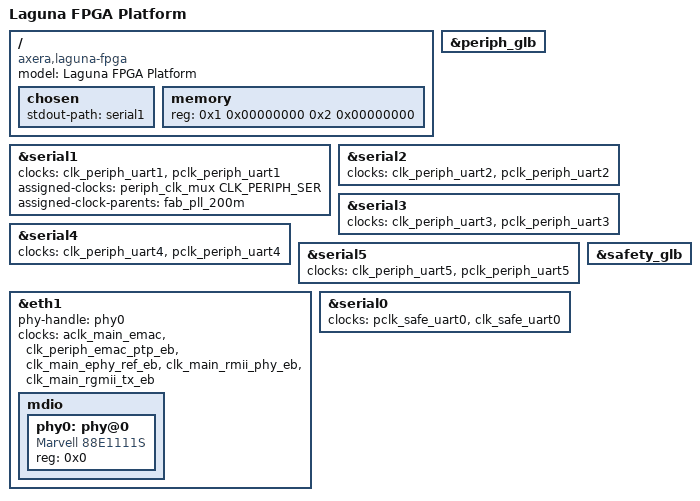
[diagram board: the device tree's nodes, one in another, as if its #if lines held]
/* SPDX-License-Identifier: GPL-2.0+
 *
 * Laguna FPGA Platform device tree
 *
 * Copyright (C) 2024 Charleye <wangkart@aliyun.com>
 */

/dts-v1/;
#include <dt-bindings/interrupt-controller/arm-gic.h>
#include <dt-bindings/mfd/laguna-syscon.h>
#include <dt-bindings/mfd/laguna-cru.h>
#include <dt-bindings/reset/laguna-reset.h>
#include <dt-bindings/clock/laguna-clock.h>

#include "laguna-global-ctrl.dtsi"
#include "laguna-clocks-fpga.dtsi"
#if defined(CONFIG_CLK_AXERA_V2)
#include "laguna-cru-v2.dtsi"
#elif defined(CONFIG_CLK_AXERA_V1)
#include "laguna-cru.dtsi"
#endif
#include "laguna.dtsi"

#if defined(CONFIG_LUA_SAFETY_INIT)
#include "laguna-safety-clocks-fpga.dtsi"
#if defined(CONFIG_CLK_AXERA_V2)
#include "laguna-safety-cru-v2.dtsi"
#elif defined(CONFIG_CLK_AXERA_V1)
#include "laguna-safety-cru.dtsi"
#endif
#include "laguna-safety.dtsi"
#endif

/ {
	model = "Laguna FPGA Platform";
	compatible = "axera,laguna-fpga";

	chosen {
		stdout-path = "serial1";
	};

	memory {
		reg = <0x1 0x00000000 0x2 0x00000000>;
		device_type = "memory";
	};
};

&periph_glb {
	status = "okay";
};

&serial1 {
#if defined(CONFIG_CLK_AXERA_V1)
	clocks = <&clk_periph_uart1>, <&pclk_periph_uart1>;
#elif defined(CONFIG_CLK_AXERA_V2)
	clocks = <&periph_clk_gate_0 PCLK_PERIPH_UART1>,
	         <&periph_clk_gate_0 CLK_PERIPH_UART1>;
#endif
	clock-names = "apb_pclk", "baudclk";
	status = "okay";
	assigned-clocks = <&periph_clk_mux CLK_PERIPH_SER>;
	assigned-clock-parents = <&fab_pll_200m>;
};

&serial2 {
#if defined(CONFIG_CLK_AXERA_V1)
	clocks = <&clk_periph_uart2>, <&pclk_periph_uart2>;
#elif defined(CONFIG_CLK_AXERA_V2)
	clocks = <&periph_clk_gate_0 PCLK_PERIPH_UART2>,
	         <&periph_clk_gate_0 CLK_PERIPH_UART2>;
#endif
	clock-names = "apb_pclk", "baudclk";
	status = "okay";
};

&serial3 {
#if defined(CONFIG_CLK_AXERA_V1)
	clocks = <&clk_periph_uart3>, <&pclk_periph_uart3>;
#elif defined(CONFIG_CLK_AXERA_V2)
	clocks = <&periph_clk_gate_0 PCLK_PERIPH_UART3>,
	         <&periph_clk_gate_0 CLK_PERIPH_UART3>;
#endif
	clock-names = "apb_pclk", "baudclk";
	status = "okay";
};

&serial4 {
#if defined(CONFIG_CLK_AXERA_V1)
	clocks = <&clk_periph_uart4>, <&pclk_periph_uart4>;
#elif defined(CONFIG_CLK_AXERA_V2)
	clocks = <&periph_clk_gate_0 PCLK_PERIPH_UART4>,
	         <&periph_clk_gate_0 CLK_PERIPH_UART4>;
#endif
	clock-names = "apb_pclk", "baudclk";
	status = "okay";
};

&serial5 {
#if defined(CONFIG_CLK_AXERA_V1)
	clocks = <&clk_periph_uart5>, <&pclk_periph_uart5>;
#elif defined(CONFIG_CLK_AXERA_V2)
	clocks = <&periph_clk_gate_0 PCLK_PERIPH_UART5>,
	         <&periph_clk_gate_0 CLK_PERIPH_UART5>;
#endif
	clock-names = "apb_pclk", "baudclk";
	status = "okay";
};

&eth1 {
	phy-handle = <&phy0>;
	status = "okay";
#if defined(CONFIG_CLK_AXERA_V1)
	clocks = <&aclk_main_emac>,
	         <&clk_periph_emac_ptp_eb>,
	         <&clk_main_ephy_ref_eb>,
	         <&clk_main_rmii_phy_eb>,
	         <&clk_main_rgmii_tx_eb>;
#elif defined(CONFIG_CLK_AXERA_V2)
	clocks = <&periph_clk_gate_1 ACLK_MAIN_EMAC>,
	         <&periph_clk_mux_gate CLK_PERIPH_EMAC_PTP_EB>,
	         <&periph_clk_mux_gate CLK_MAIN_EPHY_REF_EB>,
	         <&periph_clk_mux_gate CLK_MAIN_RMII_PHY_EB>,
	         <&periph_clk_mux_gate CLK_MAIN_RGMII_TX_EB>;
#endif
	clock-names = "aclk_eqos", "ptp_ref",
	              "ephy_ref", "rmii_phy",
	              "rgmii_tx";

	mdio {
		#address-cells = <0x1>;
		#size-cells = <0x0>;
		phy0: phy@0 {
			compatible = "Marvell 88E1111S";
			device_type = "ethernet-phy";
			reg = <0x0>;
		};
	};
};

#if defined(CONFIG_LUA_SAFETY_INIT)
&safety_glb {
	status = "okay";
};

&serial0 {
#if defined(CONFIG_CLK_AXERA_V1)
	clocks = <&pclk_safe_uart0>, <&clk_safe_uart0>;
#elif defined(CONFIG_CLK_AXERA_V2)
	clocks = <&safety_clk_gate_1 PCLK_SAFE_UART0>,
	         <&safety_clk_gate_1 CLK_SAFE_UART0>;
#endif
	clock-names = "apb_pclk", "baudclk";
	status = "okay";
};
#endif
